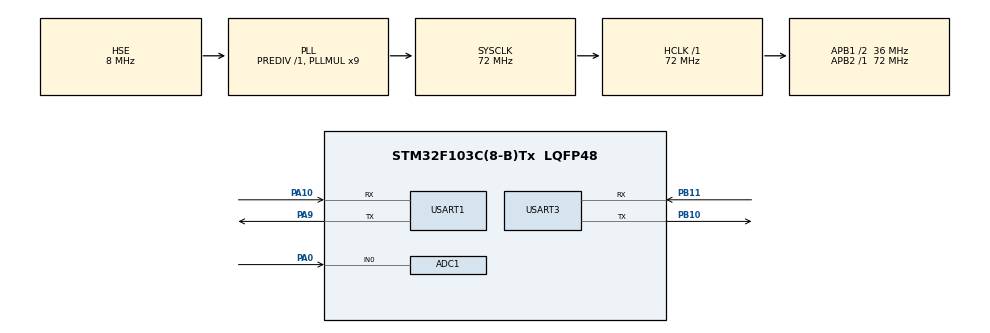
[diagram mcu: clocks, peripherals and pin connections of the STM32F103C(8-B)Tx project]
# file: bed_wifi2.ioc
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ADC1.Channel-0\#ChannelRegularConversion=ADC_CHANNEL_0
ADC1.NbrOfConversionFlag=1
ADC1.Rank-0\#ChannelRegularConversion=1
ADC1.SamplingTime-0\#ChannelRegularConversion=ADC_SAMPLETIME_1CYCLE_5
ADC1.master=1
Mcu.Family=STM32F1
Mcu.Name=STM32F103C(8-B)Tx
Mcu.Package=LQFP48
NVIC.PriorityGroup=NVIC_PRIORITYGROUP_4
NVIC.TIM2_IRQn=true\:0\:0\:false\:false\:true\:true\:true
PA0-WKUP.Signal=ADCx_IN0
PA10.Mode=Asynchronous
PA10.Signal=USART1_RX
PA13.Mode=Serial_Wire
PA13.Signal=SYS_JTMS-SWDIO
PA14.Mode=Serial_Wire
PA14.Signal=SYS_JTCK-SWCLK
PA9.Mode=Asynchronous
PA9.Signal=USART1_TX
PB10.Mode=Asynchronous
PB10.Signal=USART3_TX
PB11.Mode=Asynchronous
PB11.Signal=USART3_RX
PD0-OSC_IN.Mode=HSE-External-Oscillator
PD0-OSC_IN.Signal=RCC_OSC_IN
PD1-OSC_OUT.Mode=HSE-External-Oscillator
PD1-OSC_OUT.Signal=RCC_OSC_OUT
ProjectManager.HeapSize=0x200
ProjectManager.StackSize=0x400
ProjectManager.TargetToolchain=MDK-ARM V5
RCC.ADCPresc=RCC_ADCPCLK2_DIV8
RCC.AHBFreq_Value=72000000
RCC.APB1CLKDivider=RCC_HCLK_DIV2
RCC.APB1Freq_Value=36000000
RCC.APB1TimFreq_Value=72000000
RCC.APB2Freq_Value=72000000
RCC.APB2TimFreq_Value=72000000
RCC.HCLKFreq_Value=72000000
RCC.PLLMUL=RCC_PLL_MUL9
RCC.PLLSourceVirtual=RCC_PLLSOURCE_HSE
RCC.SYSCLKFreq_VALUE=72000000
RCC.SYSCLKSource=RCC_SYSCLKSOURCE_PLLCLK
RCC.USBFreq_Value=72000000
SH.ADCx_IN0.0=ADC1_IN0,IN0
TIM2.Period=100-1
TIM2.Prescaler=36000-1
USART1.VirtualMode=VM_ASYNC
USART3.VirtualMode=VM_ASYNC
VP_TIM2_VS_ClockSourceINT.Mode=Internal
board=custom

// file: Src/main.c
/* USER CODE BEGIN Header */
/**
  ******************************************************************************
  * @file           : main.c
  * @brief          : Main program body
  ******************************************************************************
  * @attention
  *
  * <h2><center>&copy; Copyright (c) 2022 STMicroelectronics.
  * All rights reserved.</center></h2>
  *
  * This software component is licensed by ST under BSD 3-Clause license,
  * the "License"; You may not use this file except in compliance with the
  * License. You may obtain a copy of the License at:
  *                        opensource.org/licenses/BSD-3-Clause
  *
  ******************************************************************************
  */
/* USER CODE END Header */

#include "main.h"
#include "adc.h"
#include "tim.h"
#include "usart.h"
#include "gpio.h"

/* USER CODE BEGIN Includes */
#include <stdlib.h>
#include "stdio.h"
#include "string.h"

/* USER CODE END Includes */

#define API_KEY           "H5tWmSoy2SZmv2YJAUWQ1hb8qXw="
#define DEVICE_ID 				"855715723"                     //wujing

/* USER CODE BEGIN PTD */
extern __IO uint32_t ADC_ConvertedValue;
/* USER CODE END PTD */
uint32_t Task_Delay[NumOfTask]={0};

void SystemClock_Config(void);

/* USER CODE BEGIN 0 */
//static void Delay(__IO uint32_t nCount)	 //简单的延时函数
//{
//	for(; nCount != 0; nCount--);
//}
/* USER CODE END 0 */

int main(void)
{
  /* USER CODE BEGIN 1 */
   float ADC_Vol = 0;
   uint8_t a = 1;

//	uint8_t show_flag = 0;
//	char pucBuff[20];
	char databuff[128];
//	char *p;
//	uint8_t send_flag = 0;
//  char yali[128];
  	char temp[128];
  /* USER CODE END 1 */

  /* MCU Configuration--------------------------------------------------------*/

  /* Reset of all peripherals, Initializes the Flash interface and the Systick. */
  HAL_Init();

  /* Configure the system clock */
  SystemClock_Config();

  /* Initialize all configured peripherals */
  MX_GPIO_Init();
  MX_ADC1_Init();
  Rheostat_Init();
  MX_TIM2_Init();
  MX_USART1_UART_Init();
  MX_USART3_UART_Init();
  /* USER CODE BEGIN 2 */
  HAL_UART_Receive_IT(&huart3,(uint8_t *)UART1_temp,REC_LENGTH);
//  HAL_TIM_Base_Start_IT(&htim2); //开启定时器1中断
    HAL_Delay(1000);
	printf("WIFI init...      \n\r");
  HAL_Delay(1000);
	esp8266Init();
  printf("WIFI init success\n\r");
  /* USER CODE END 2 */

  /* Infinite loop */
  /* USER CODE BEGIN WHILE */
  while (1)
  {

    HAL_ADC_Start(&hadc1);     //启动ADC转换

    ADC_Vol = HAL_ADC_GetValue(&hadc1);   //获取AD值}
    ADC_Vol =(float) (HAL_ADC_GetValue(&hadc1))/4096*(float)3.3-0.6; // 读取转换的AD值

    printf("第%d次测试数据\r\n",a);
    a++;
    printf("              当前ADC_Vol的值为：%.2fV\r\n",ADC_Vol);
    sprintf(databuff,"{\"presure\":%.2f}\r\n",ADC_Vol);
    sprintf(temp,"Content-Length:%d\r\n\r\n",strlen(databuff));																												//计算发送数据的长度
    sprintf((char *)send_buff,"POST /devices/%s/datapoints?type=3 HTTP/1.1\r\napi-key: %s\r\nHost:api.heclouds.com\r\n",DEVICE_ID,API_KEY);
    //构建POST报文，传入设备ID和产品的API-KEY
    strcat((char *)send_buff,temp);
    strcat((char *)send_buff,databuff);
    My_String_Printf1(send_buff);
    HAL_Delay(2000);

  /* USER CODE END 3 */
}
}
void SystemClock_Config(void)
{
  RCC_OscInitTypeDef RCC_OscInitStruct = {0};
  RCC_ClkInitTypeDef RCC_ClkInitStruct = {0};
  RCC_PeriphCLKInitTypeDef PeriphClkInit = {0};

  /** Initializes the CPU, AHB and APB busses clocks
  */
  RCC_OscInitStruct.OscillatorType = RCC_OSCILLATORTYPE_HSE;
  RCC_OscInitStruct.HSEState = RCC_HSE_ON;
  RCC_OscInitStruct.HSEPredivValue = RCC_HSE_PREDIV_DIV1;
  RCC_OscInitStruct.HSIState = RCC_HSI_ON;
  RCC_OscInitStruct.PLL.PLLState = RCC_PLL_ON;
  RCC_OscInitStruct.PLL.PLLSource = RCC_PLLSOURCE_HSE;
  RCC_OscInitStruct.PLL.PLLMUL = RCC_PLL_MUL9;
  if (HAL_RCC_OscConfig(&RCC_OscInitStruct) != HAL_OK)
  {
    Error_Handler();
  }
  /** Initializes the CPU, AHB and APB busses clocks
  */
  RCC_ClkInitStruct.ClockType = RCC_CLOCKTYPE_HCLK|RCC_CLOCKTYPE_SYSCLK
                              |RCC_CLOCKTYPE_PCLK1|RCC_CLOCKTYPE_PCLK2;
  RCC_ClkInitStruct.SYSCLKSource = RCC_SYSCLKSOURCE_PLLCLK;
  RCC_ClkInitStruct.AHBCLKDivider = RCC_SYSCLK_DIV1;
  RCC_ClkInitStruct.APB1CLKDivider = RCC_HCLK_DIV2;
  RCC_ClkInitStruct.APB2CLKDivider = RCC_HCLK_DIV1;

  if (HAL_RCC_ClockConfig(&RCC_ClkInitStruct, FLASH_LATENCY_2) != HAL_OK)
  {
    Error_Handler();
  }
  PeriphClkInit.PeriphClockSelection = RCC_PERIPHCLK_ADC;
  PeriphClkInit.AdcClockSelection = RCC_ADCPCLK2_DIV6;
  if (HAL_RCCEx_PeriphCLKConfig(&PeriphClkInit) != HAL_OK)
  {
    Error_Handler();
  }
}

void Error_Handler(void)
{
}

/************************ (C) COPYRIGHT STMicroelectronics *****END OF FILE****/
